# STM32H745xx_CM4 register map
File version: 1.0
Registers are 32-bit, read-write, reset 0x0 unless marked. A register's access mark holds for its fields unless they carry their own. Offsets are from the block's base; [hi:lo] are bit positions; 'fields as' and 'values as' point back to an identical list.

## FMC_Bank1E_R — Flexible Memory Controller Bank1E
Base 0x52004104
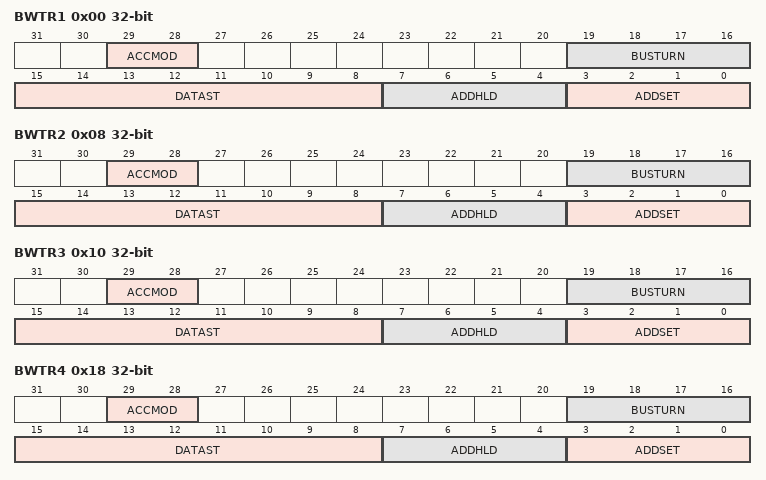
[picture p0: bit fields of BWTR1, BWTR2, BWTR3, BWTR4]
0x00 BWTR1 — NOR/PSRAM write timing registers
  [29:28] ACCMOD — ACCMOD[1:0] bits (Access mode)
  [19:16] BUSTURN — BUSTURN[3:0] bits (Bus turnaround phase duration)
  [15:8] DATAST — DATAST [3:0] bits (Data-phase duration)
  [7:4] ADDHLD — ADDHLD[3:0] bits (Address-hold phase duration)
  [3:0] ADDSET — ADDSET[3:0] bits (Address setup phase duration)
0x08 BWTR2 — NOR/PSRAM write timing registers
  fields as BWTR1
0x10 BWTR3 — NOR/PSRAM write timing registers
  fields as BWTR1
0x18 BWTR4 — NOR/PSRAM write timing registers
  fields as BWTR1

## FMC_Bank5_6_R — Flexible Memory Controller Bank5 and 6
Base 0x52004140
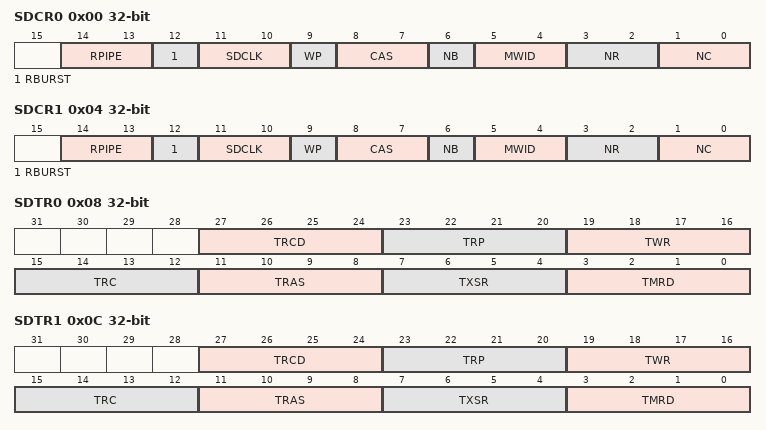
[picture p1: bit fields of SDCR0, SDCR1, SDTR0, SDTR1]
0x00 SDCR0 — SDRAM Control registers
  [14:13] RPIPE — Write protection
  [12] RBURST — Read burst
  [11:10] SDCLK — SDRAM clock configuration
  [9] WP — Write protection
  [8:7] CAS — CAS[1:0] bits (CAS latency)
  [6] NB — Number of internal bank
  [5:4] MWID — NR[1:0] bits (Number of row bits)
  [3:2] NR — NR[1:0] bits (Number of row bits)
  [1:0] NC — NC[1:0] bits (Number of column bits)
0x04 SDCR1 — SDRAM Control registers
  fields as SDCR0
0x08 SDTR0 — SDRAM Timing registers
  [27:24] TRCD — TRP[2:0] bits (Row to column delay)
  [23:20] TRP — TRP[2:0] bits (Row precharge delay)
  [19:16] TWR — TRC[2:0] bits (Write recovery delay)
  [15:12] TRC — TRC[2:0] bits (Row cycle delay)
  [11:8] TRAS — TRAS[3:0] bits (Self refresh time)
  [7:4] TXSR — TXSR[3:0] bits (Exit self refresh)
  [3:0] TMRD — TMRD[3:0] bits (Load mode register to active)
0x0C SDTR1 — SDRAM Timing registers
  fields as SDTR0
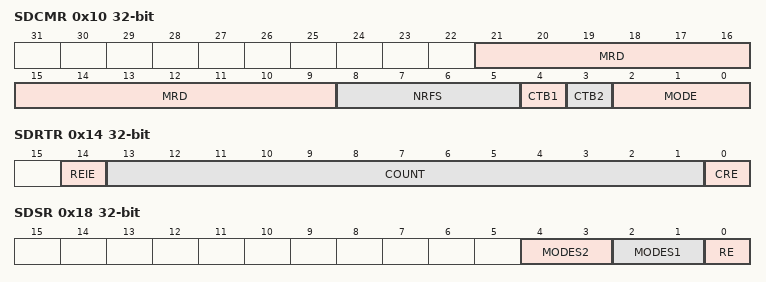
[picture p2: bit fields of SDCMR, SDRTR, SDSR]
0x10 SDCMR — SDRAM Command Mode register
  [21:9] MRD — MRD[12:0] bits (Mode register definition)
  [8:5] NRFS — NRFS[3:0] bits (Number of auto-refresh)
  [4] CTB1 — Command target 1
  [3] CTB2 — Command target 2
  [2:0] MODE — MODE[2:0] bits (Command mode)
0x14 SDRTR — SDRAM Refresh Timer register
  [14] REIE — RES interrupt enable
  [13:1] COUNT — COUNT[12:0] bits (Refresh timer count)
  [0] CRE — Clear refresh error flag
0x18 SDSR — SDRAM Status register
  [4:3] MODES2 — MODES2[1:0]bits (Status mode for bank 2)
  [2:1] MODES1 — MODES1[1:0]bits (Status mode for bank 1)
  [0] RE — Refresh error flag

## QUADSPI — QUAD Serial Peripheral Interface
Base 0x52005000
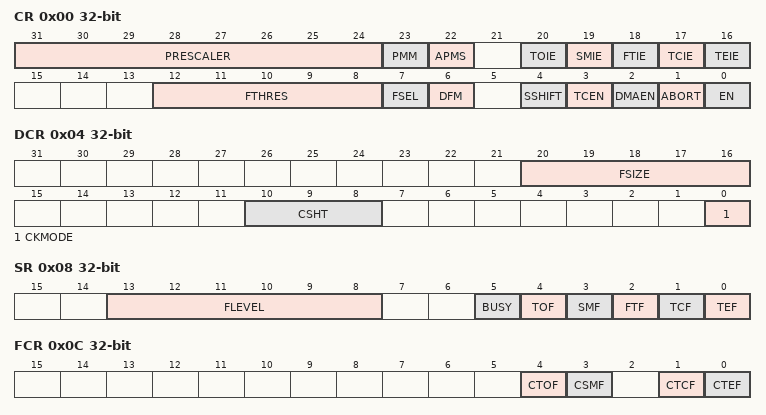
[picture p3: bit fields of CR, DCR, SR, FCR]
0x00 CR — QUADSPI Control register
  [31:24] PRESCALER — PRESCALER[7:0] Clock prescaler
  [23] PMM — Polling Match Mode
  [22] APMS — Bit 1
  [20] TOIE — TimeOut Interrupt Enable
  [19] SMIE — Status Match Interrupt Enable
  [18] FTIE — FIFO Threshold Interrupt Enable
  [17] TCIE — Transfer Complete Interrupt Enable
  [16] TEIE — Transfer Error Interrupt Enable
  [12:8] FTHRES — FTHRES[4:0] FIFO Level
  [7] FSEL — Flash Select
  [6] DFM — Dual Flash Mode
  [4] SSHIFT — SSHIFT Sample Shift
  [3] TCEN — Timeout Counter Enable
  [2] DMAEN — Reserved: needed for softawre compatibility (DMA Enable)
  [1] ABORT — Abort request
  [0] EN — Enable
0x04 DCR — QUADSPI Device Configuration register
  [20:16] FSIZE — FSIZE[4:0]: Flash Size
  [10:8] CSHT — CSHT[2:0]: ChipSelect High Time
  [0] CKMODE — Mode 0 / Mode 3
0x08 SR — QUADSPI Status register
  [13:8] FLEVEL — FIFO Threshlod Flag
  [5] BUSY
  [4] TOF — Timeout Flag
  [3] SMF — Status Match Flag
  [2] FTF — FIFO Threshlod Flag
  [1] TCF — Transfer Complete Flag
  [0] TEF — Transfer Error Flag
0x0C FCR — QUADSPI Flag Clear register
  [4] CTOF — Clear Timeout Flag
  [3] CSMF — Clear Status Match Flag
  [1] CTCF — Clear Transfer Complete Flag
  [0] CTEF — Clear Transfer Error Flag
0x10 DLR — QUADSPI Data Length register
  [31:0] DL — DL[31:0]: Data Length
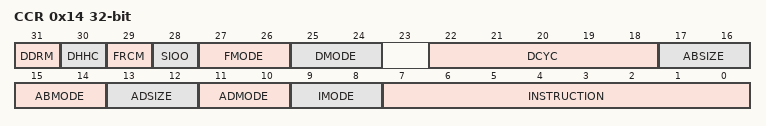
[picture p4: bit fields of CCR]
0x14 CCR — QUADSPI Communication Configuration register
  [31] DDRM — DDRM: Double Data Rate Mode
  [30] DHHC — DHHC: DDR hold half cycle
  [29] FRCM — FRCM: Free-running clock mode
  [28] SIOO — SIOO: Send Instruction Only Once Mode
  [27:26] FMODE — FMODE[1:0]: Functional Mode
  [25:24] DMODE — DMODE[1:0]: Data Mode
  [22:18] DCYC — DCYC[4:0]: Dummy Cycles
  [17:16] ABSIZE — ABSIZE[1:0]: Instruction Mode
  [15:14] ABMODE — ABMODE[1:0]: Alternate Bytes Mode
  [13:12] ADSIZE — ADSIZE[1:0]: Address Size
  [11:10] ADMODE — ADMODE[1:0]: Address Mode
  [9:8] IMODE — IMODE[1:0]: Instruction Mode
  [7:0] INSTRUCTION — INSTRUCTION[7:0]: Instruction
0x18 AR — QUADSPI Address register
  [31:0] ADDRESS — ADDRESS[31:0]: Address
0x1C ABR — QUADSPI Alternate Bytes register
  [31:0] ALTERNATE — ALTERNATE[31:0]: Alternate Bytes
0x20 DR — QUADSPI Data register
  [31:0] DATA — DATA[31:0]: Data
0x24 PSMKR — QUADSPI Polling Status Mask register
  [31:0] MASK — MASK[31:0]: Status Mask
0x28 PSMAR — QUADSPI Polling Status Match register
  [31:0] MATCH — MATCH[31:0]: Status Match
0x2C PIR — QUADSPI Polling Interval register
  [15:0] INTERVAL — INTERVAL[15:0]: Polling Interval
0x30 LPTR — QUADSPI Low Power Timeout register
  [15:0] TIMEOUT — TIMEOUT[15:0]: Timeout period
